# TM4C129ENCPDT register map
File version: 1.0
CPU: CORTEX_M4 1.0, other endian, MPU, FPU, 3 interrupt priority bits
Registers are 32-bit, read-write, reset 0x0 unless marked. A register's access mark holds for its fields unless they carry their own. Offsets are from the block's base; [hi:lo] are bit positions; {n}, {i} and the like mark numbered series.

## SYSCTL — System Control register addresses
Base 0x400FE000
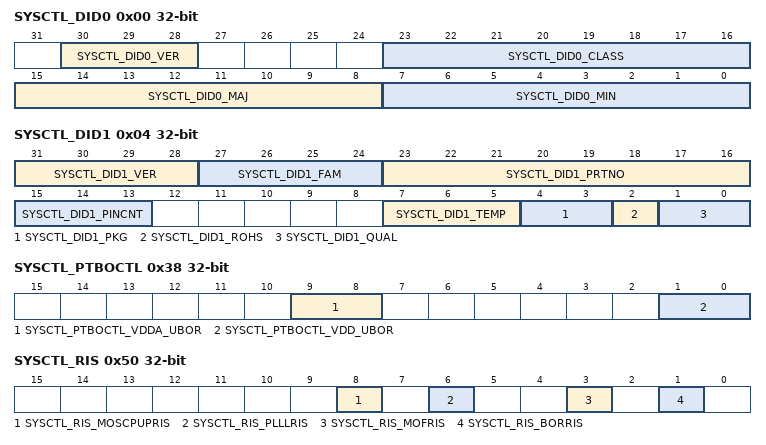
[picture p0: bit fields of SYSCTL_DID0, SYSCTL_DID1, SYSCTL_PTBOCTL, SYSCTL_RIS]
0x00 SYSCTL_DID0 — Device Identification 0
  [30:28] SYSCTL_DID0_VER — [30:28] DID0 Version
    0x10000000=Second version of the DID0 register format
  [23:16] SYSCTL_DID0_CLASS — [23:16] Device Class
    0xA0000=SYSCTL_DID0_CLASS_TM4C129 (Tiva(TM) TM4C129-class microcontrollers)
  [15:8] SYSCTL_DID0_MAJ — [15:8] Major Revision
    0=SYSCTL_DID0_MAJ_REVA (Revision A (initial device)); 0x100=SYSCTL_DID0_MAJ_REVB (Revision B (first base layer revision)); 0x200=SYSCTL_DID0_MAJ_REVC (Revision C (second base layer revision))
  [7:0] SYSCTL_DID0_MIN — [7:0] Minor Revision
    0=Initial device, or a major revision update; 1=First metal layer change; 2=Second metal layer change
0x04 SYSCTL_DID1 — Device Identification 1
  [31:28] SYSCTL_DID1_VER — [31:28] DID1 Version
  [27:24] SYSCTL_DID1_FAM — [27:24] Family
  [23:16] SYSCTL_DID1_PRTNO — [23:16] Part Number
  [15:13] SYSCTL_DID1_PINCNT — [15:13] Package Pin Count
    0x4000=100-pin LQFP package; 0x6000=64-pin LQFP package; 0x8000=144-pin LQFP package; 0xA000=157-pin BGA package; 0xC000=128-pin TQFP package
  [7:5] SYSCTL_DID1_TEMP — [7:5] Temperature Range
    0=SYSCTL_DID1_TEMP_C (Commercial temperature range); 32=SYSCTL_DID1_TEMP_I (Industrial temperature range); 64=SYSCTL_DID1_TEMP_E (Extended temperature range)
  [4:3] SYSCTL_DID1_PKG — [4:3] Package Type
    8=SYSCTL_DID1_PKG_QFP (QFP package); 16=SYSCTL_DID1_PKG_BGA (BGA package)
  [2] SYSCTL_DID1_ROHS — [2:2] RoHS-Compliance
  [1:0] SYSCTL_DID1_QUAL — [1:0] Qualification Status
    0=SYSCTL_DID1_QUAL_ES (Engineering Sample (unqualified)); 1=SYSCTL_DID1_QUAL_PP (Pilot Production (unqualified)); 2=SYSCTL_DID1_QUAL_FQ (Fully Qualified)
0x38 SYSCTL_PTBOCTL — Power-Temp Brown Out Control
  [9:8] SYSCTL_PTBOCTL_VDDA_UBOR — [9:8] VDDA under BOR Event Action
    0=SYSCTL_PTBOCTL_VDDA_UBOR_NONE (No Action); 0x100=SYSCTL_PTBOCTL_VDDA_UBOR_SYSINT (System control interrupt); 0x200=SYSCTL_PTBOCTL_VDDA_UBOR_NMI (NMI); 0x300=SYSCTL_PTBOCTL_VDDA_UBOR_RST (Reset)
  [1:0] SYSCTL_PTBOCTL_VDD_UBOR — [1:0] VDD (VDDS) under BOR Event Action
    0=SYSCTL_PTBOCTL_VDD_UBOR_NONE (No Action); 1=SYSCTL_PTBOCTL_VDD_UBOR_SYSINT (System control interrupt); 2=SYSCTL_PTBOCTL_VDD_UBOR_NMI (NMI); 3=SYSCTL_PTBOCTL_VDD_UBOR_RST (Reset)
0x50 SYSCTL_RIS — Raw Interrupt Status
  [8] SYSCTL_RIS_MOSCPUPRIS — [8:8] MOSC Power Up Raw Interrupt Status
  [6] SYSCTL_RIS_PLLLRIS — [6:6] PLL Lock Raw Interrupt Status
  [3] SYSCTL_RIS_MOFRIS — [3:3] Main Oscillator Failure Raw Interrupt Status
  [1] SYSCTL_RIS_BORRIS — [1:1] Brown-Out Reset Raw Interrupt Status
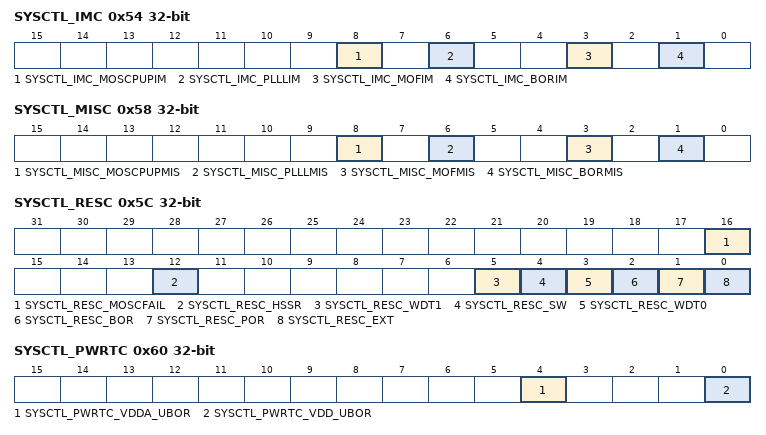
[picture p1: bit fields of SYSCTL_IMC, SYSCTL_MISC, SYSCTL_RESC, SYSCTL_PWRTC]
0x54 SYSCTL_IMC — Interrupt Mask Control
  [8] SYSCTL_IMC_MOSCPUPIM — [8:8] MOSC Power Up Interrupt Mask
  [6] SYSCTL_IMC_PLLLIM — [6:6] PLL Lock Interrupt Mask
  [3] SYSCTL_IMC_MOFIM — [3:3] Main Oscillator Failure Interrupt Mask
  [1] SYSCTL_IMC_BORIM — [1:1] Brown-Out Reset Interrupt Mask
0x58 SYSCTL_MISC — Masked Interrupt Status and Clear
  [8] SYSCTL_MISC_MOSCPUPMIS — [8:8] MOSC Power Up Masked Interrupt Status
  [6] SYSCTL_MISC_PLLLMIS — [6:6] PLL Lock Masked Interrupt Status
  [3] SYSCTL_MISC_MOFMIS — [3:3] Main Oscillator Failure Masked Interrupt Status
  [1] SYSCTL_MISC_BORMIS — [1:1] BOR Masked Interrupt Status
0x5C SYSCTL_RESC — Reset Cause
  [16] SYSCTL_RESC_MOSCFAIL — [16:16] MOSC Failure Reset
  [12] SYSCTL_RESC_HSSR — [12:12] HSSR Reset
  [5] SYSCTL_RESC_WDT1 — [5:5] Watchdog Timer 1 Reset
  [4] SYSCTL_RESC_SW — [4:4] Software Reset
  [3] SYSCTL_RESC_WDT0 — [3:3] Watchdog Timer 0 Reset
  [2] SYSCTL_RESC_BOR — [2:2] Brown-Out Reset
  [1] SYSCTL_RESC_POR — [1:1] Power-On Reset
  [0] SYSCTL_RESC_EXT — [0:0] External Reset
0x60 SYSCTL_PWRTC — Power-Temperature Cause
  [4] SYSCTL_PWRTC_VDDA_UBOR — [4:4] VDDA Under BOR Status
  [0] SYSCTL_PWRTC_VDD_UBOR — [0:0] VDD Under BOR Status
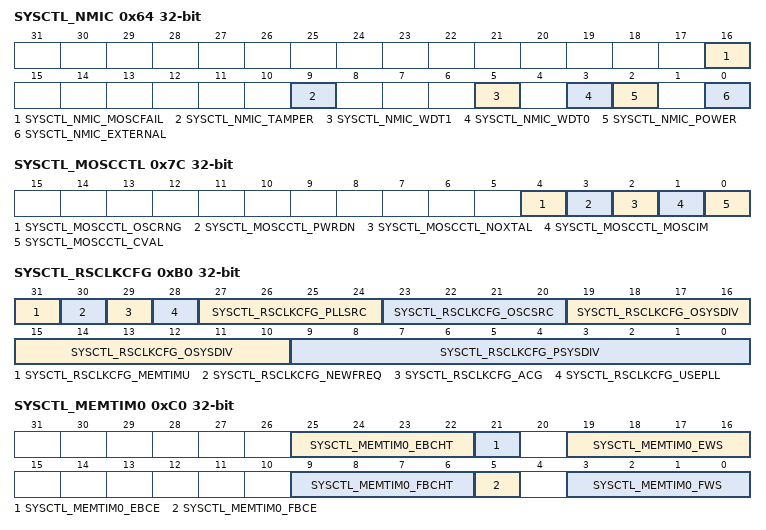
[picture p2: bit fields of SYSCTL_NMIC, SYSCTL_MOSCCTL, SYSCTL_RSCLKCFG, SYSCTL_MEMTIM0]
0x64 SYSCTL_NMIC — NMI Cause Register
  [16] SYSCTL_NMIC_MOSCFAIL — [16:16] MOSC Failure NMI
  [9] SYSCTL_NMIC_TAMPER — [9:9] Tamper Event NMI
  [5] SYSCTL_NMIC_WDT1 — [5:5] Watch Dog Timer (WDT) 1 NMI
  [3] SYSCTL_NMIC_WDT0 — [3:3] Watch Dog Timer (WDT) 0 NMI
  [2] SYSCTL_NMIC_POWER — [2:2] Power/Brown Out Event NMI
  [0] SYSCTL_NMIC_EXTERNAL — [0:0] External Pin NMI
0x7C SYSCTL_MOSCCTL — Main Oscillator Control
  [4] SYSCTL_MOSCCTL_OSCRNG — [4:4] Oscillator Range
  [3] SYSCTL_MOSCCTL_PWRDN — [3:3] Power Down
  [2] SYSCTL_MOSCCTL_NOXTAL — [2:2] No Crystal Connected
  [1] SYSCTL_MOSCCTL_MOSCIM — [1:1] MOSC Failure Action
  [0] SYSCTL_MOSCCTL_CVAL — [0:0] Clock Validation for MOSC
0xB0 SYSCTL_RSCLKCFG — Run and Sleep Mode Configuration Register
  [31] SYSCTL_RSCLKCFG_MEMTIMU — [31:31] Memory Timing Register Update
  [30] SYSCTL_RSCLKCFG_NEWFREQ — [30:30] New PLLFREQ Accept
  [29] SYSCTL_RSCLKCFG_ACG — [29:29] Auto Clock Gating
  [28] SYSCTL_RSCLKCFG_USEPLL — [28:28] Use PLL
  [27:24] SYSCTL_RSCLKCFG_PLLSRC — [27:24] PLL Source
    0=SYSCTL_RSCLKCFG_PLLSRC_PIOSC (PIOSC is PLL input clock source); 0x3000000=SYSCTL_RSCLKCFG_PLLSRC_MOSC (MOSC is the PLL input clock source)
  [23:20] SYSCTL_RSCLKCFG_OSCSRC — [23:20] Oscillator Source
    0=SYSCTL_RSCLKCFG_OSCSRC_PIOSC (PIOSC is oscillator source); 0x200000=SYSCTL_RSCLKCFG_OSCSRC_LFIOSC (LFIOSC is oscillator source); 0x300000=SYSCTL_RSCLKCFG_OSCSRC_MOSC (MOSC is oscillator source); 0x400000=SYSCTL_RSCLKCFG_OSCSRC_RTC (Hibernation Module RTC Oscillator (RTCOSC))
  [19:10] SYSCTL_RSCLKCFG_OSYSDIV — [19:10] Oscillator System Clock Divisor
  [9:0] SYSCTL_RSCLKCFG_PSYSDIV — [9:0] PLL System Clock Divisor
0xC0 SYSCTL_MEMTIM0 — Memory Timing Parameter Register 0 for Main Flash and EEPROM
  [25:22] SYSCTL_MEMTIM0_EBCHT — [25:22] EEPROM Clock High Time
    0=SYSCTL_MEMTIM0_EBCHT_0_5 (1/2 system clock period); 0x400000=1 system clock period; 0x800000=SYSCTL_MEMTIM0_EBCHT_1_5 (1.5 system clock periods); 0xC00000=2 system clock periods; 0x1000000=SYSCTL_MEMTIM0_EBCHT_2_5 (2.5 system clock periods); 0x1400000=3 system clock periods; 0x1800000=SYSCTL_MEMTIM0_EBCHT_3_5 (3.5 system clock periods); 0x1C00000=4 system clock periods; 0x2000000=SYSCTL_MEMTIM0_EBCHT_4_5 (4.5 system clock periods)
  [21] SYSCTL_MEMTIM0_EBCE — [21:21] EEPROM Bank Clock Edge
  [19:16] SYSCTL_MEMTIM0_EWS — [19:16] EEPROM Wait States
  [9:6] SYSCTL_MEMTIM0_FBCHT — [9:6] Flash Bank Clock High Time
    0=SYSCTL_MEMTIM0_FBCHT_0_5 (1/2 system clock period); 64=1 system clock period; 128=SYSCTL_MEMTIM0_FBCHT_1_5 (1.5 system clock periods); 192=2 system clock periods; 0x100=SYSCTL_MEMTIM0_FBCHT_2_5 (2.5 system clock periods); 0x140=3 system clock periods; 0x180=SYSCTL_MEMTIM0_FBCHT_3_5 (3.5 system clock periods); 0x1C0=4 system clock periods; 0x200=SYSCTL_MEMTIM0_FBCHT_4_5 (4.5 system clock periods)
  [5] SYSCTL_MEMTIM0_FBCE — [5:5] Flash Bank Clock Edge
  [3:0] SYSCTL_MEMTIM0_FWS — [3:0] Flash Wait State
0x138 SYSCTL_ALTCLKCFG — Alternate Clock Configuration
  [3:0] SYSCTL_ALTCLKCFG_ALTCLK — [3:0] Alternate Clock Source
    0=SYSCTL_ALTCLKCFG_ALTCLK_PIOSC (PIOSC); 3=SYSCTL_ALTCLKCFG_ALTCLK_RTCOSC (Hibernation Module Real-time clock output (RTCOSC)); 4=SYSCTL_ALTCLKCFG_ALTCLK_LFIOSC (Low-frequency internal oscillator (LFIOSC))
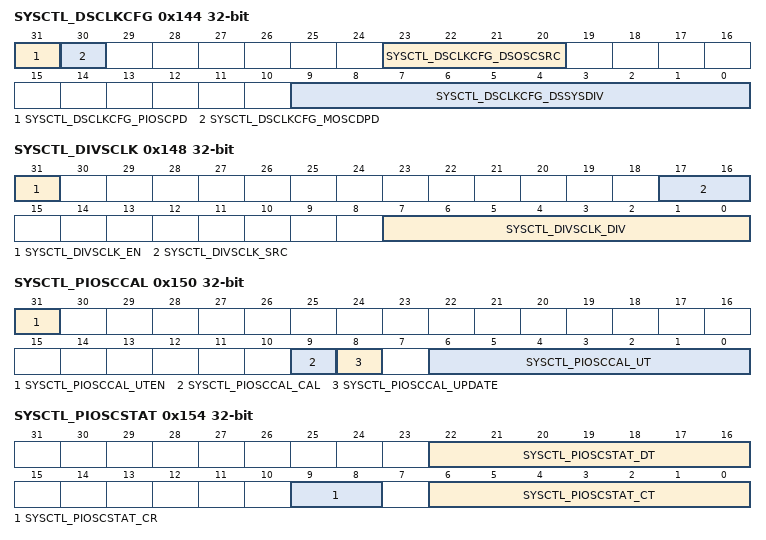
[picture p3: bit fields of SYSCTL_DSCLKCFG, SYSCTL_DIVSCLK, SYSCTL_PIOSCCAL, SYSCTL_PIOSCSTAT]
0x144 SYSCTL_DSCLKCFG — Deep Sleep Clock Configuration Register
  [31] SYSCTL_DSCLKCFG_PIOSCPD — [31:31] PIOSC Power Down
  [30] SYSCTL_DSCLKCFG_MOSCDPD — [30:30] MOSC Disable Power Down
  [23:20] SYSCTL_DSCLKCFG_DSOSCSRC — [23:20] Deep Sleep Oscillator Source
    0=SYSCTL_DSCLKCFG_DSOSCSRC_PIOSC (PIOSC); 0x200000=SYSCTL_DSCLKCFG_DSOSCSRC_LFIOSC (LFIOSC); 0x300000=SYSCTL_DSCLKCFG_DSOSCSRC_MOSC (MOSC); 0x400000=SYSCTL_DSCLKCFG_DSOSCSRC_RTC (Hibernation Module RTCOSC)
  [9:0] SYSCTL_DSCLKCFG_DSSYSDIV — [9:0] Deep Sleep Clock Divisor
0x148 SYSCTL_DIVSCLK — Divisor and Source Clock Configuration
  [31] SYSCTL_DIVSCLK_EN — [31:31] DIVSCLK Enable
  [17:16] SYSCTL_DIVSCLK_SRC — [17:16] Clock Source
    0=SYSCTL_DIVSCLK_SRC_SYSCLK (System Clock); 0x10000=SYSCTL_DIVSCLK_SRC_PIOSC (PIOSC); 0x20000=SYSCTL_DIVSCLK_SRC_MOSC (MOSC)
  [7:0] SYSCTL_DIVSCLK_DIV — [7:0] Divisor Value
0x14C SYSCTL_SYSPROP — System Properties
  [0] SYSCTL_SYSPROP_FPU — [0:0] FPU Present
0x150 SYSCTL_PIOSCCAL — Precision Internal Oscillator Calibration
  [31] SYSCTL_PIOSCCAL_UTEN — [31:31] Use User Trim Value
  [9] SYSCTL_PIOSCCAL_CAL — [9:9] Start Calibration
  [8] SYSCTL_PIOSCCAL_UPDATE — [8:8] Update Trim
  [6:0] SYSCTL_PIOSCCAL_UT — [6:0] User Trim Value
0x154 SYSCTL_PIOSCSTAT — Precision Internal Oscillator Statistics
  [22:16] SYSCTL_PIOSCSTAT_DT — [22:16] Default Trim Value
  [9:8] SYSCTL_PIOSCSTAT_CR — [9:8] Calibration Result
    0=SYSCTL_PIOSCSTAT_CRNONE (Calibration has not been attempted); 0x100=SYSCTL_PIOSCSTAT_CRPASS (The last calibration operation completed to meet 1% accuracy); 0x200=SYSCTL_PIOSCSTAT_CRFAIL (The last calibration operation failed to meet 1% accuracy)
  [6:0] SYSCTL_PIOSCSTAT_CT — [6:0] Calibration Trim Value
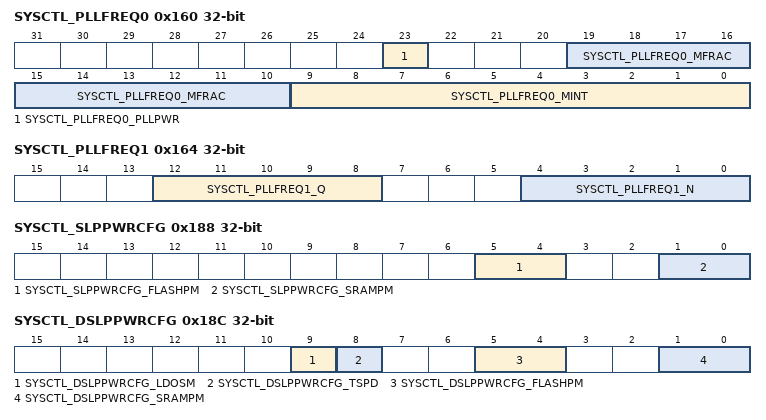
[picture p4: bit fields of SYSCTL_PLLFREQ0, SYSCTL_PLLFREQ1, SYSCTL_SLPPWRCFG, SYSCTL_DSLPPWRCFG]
0x160 SYSCTL_PLLFREQ0 — PLL Frequency 0
  [23] SYSCTL_PLLFREQ0_PLLPWR — [23:23] PLL Power
  [19:10] SYSCTL_PLLFREQ0_MFRAC — [19:10] PLL M Fractional Value
  [9:0] SYSCTL_PLLFREQ0_MINT — [9:0] PLL M Integer Value
0x164 SYSCTL_PLLFREQ1 — PLL Frequency 1
  [12:8] SYSCTL_PLLFREQ1_Q — [12:8] PLL Q Value
  [4:0] SYSCTL_PLLFREQ1_N — [4:0] PLL N Value
0x168 SYSCTL_PLLSTAT — PLL Status
  [0] SYSCTL_PLLSTAT_LOCK — [0:0] PLL Lock
0x188 SYSCTL_SLPPWRCFG — Sleep Power Configuration
  [5:4] SYSCTL_SLPPWRCFG_FLASHPM — [5:4] Flash Power Modes
    0=SYSCTL_SLPPWRCFG_FLASHPM_NRM (Active Mode); 32=SYSCTL_SLPPWRCFG_FLASHPM_SLP (Low Power Mode)
  [1:0] SYSCTL_SLPPWRCFG_SRAMPM — [1:0] SRAM Power Modes
    0=SYSCTL_SLPPWRCFG_SRAMPM_NRM (Active Mode); 1=SYSCTL_SLPPWRCFG_SRAMPM_SBY (Standby Mode); 3=SYSCTL_SLPPWRCFG_SRAMPM_LP (Low Power Mode)
0x18C SYSCTL_DSLPPWRCFG — Deep-Sleep Power Configuration
  [9] SYSCTL_DSLPPWRCFG_LDOSM — [9:9] LDO Sleep Mode
  [8] SYSCTL_DSLPPWRCFG_TSPD — [8:8] Temperature Sense Power Down
  [5:4] SYSCTL_DSLPPWRCFG_FLASHPM — [5:4] Flash Power Modes
    0=SYSCTL_DSLPPWRCFG_FLASHPM_NRM (Active Mode); 32=SYSCTL_DSLPPWRCFG_FLASHPM_SLP (Low Power Mode)
  [1:0] SYSCTL_DSLPPWRCFG_SRAMPM — [1:0] SRAM Power Modes
    0=SYSCTL_DSLPPWRCFG_SRAMPM_NRM (Active Mode); 1=SYSCTL_DSLPPWRCFG_SRAMPM_SBY (Standby Mode); 3=SYSCTL_DSLPPWRCFG_SRAMPM_LP (Low Power Mode)
0x1A0 SYSCTL_NVMSTAT — Non-Volatile Memory Information
  [0] SYSCTL_NVMSTAT_FWB — [0:0] 32 Word Flash Write Buffer Available
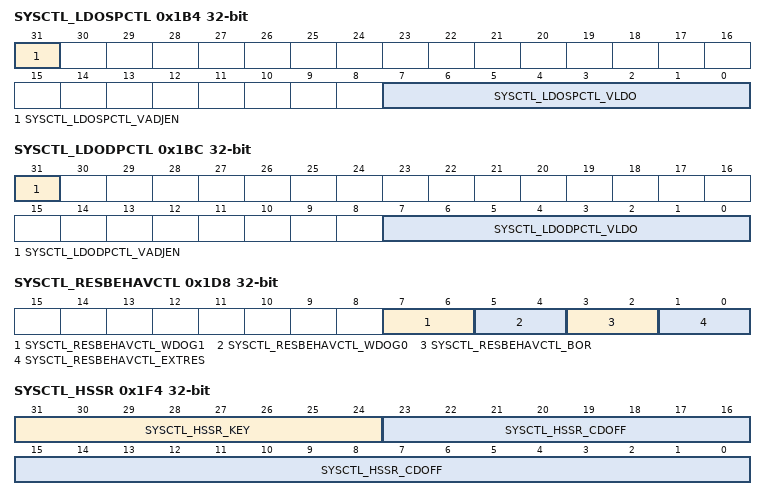
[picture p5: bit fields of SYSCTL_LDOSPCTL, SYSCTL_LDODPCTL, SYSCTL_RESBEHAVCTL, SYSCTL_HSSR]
0x1B4 SYSCTL_LDOSPCTL — LDO Sleep Power Control
  [31] SYSCTL_LDOSPCTL_VADJEN — [31:31] Voltage Adjust Enable
  [7:0] SYSCTL_LDOSPCTL_VLDO — [7:0] LDO Output Voltage
    18=SYSCTL_LDOSPCTL_VLDO_0_90V (0.90 V); 19=SYSCTL_LDOSPCTL_VLDO_0_95V (0.95 V); 20=SYSCTL_LDOSPCTL_VLDO_1_00V (1.00 V); 21=SYSCTL_LDOSPCTL_VLDO_1_05V (1.05 V); 22=SYSCTL_LDOSPCTL_VLDO_1_10V (1.10 V); 23=SYSCTL_LDOSPCTL_VLDO_1_15V (1.15 V); 24=SYSCTL_LDOSPCTL_VLDO_1_20V (1.20 V)
0x1BC SYSCTL_LDODPCTL — LDO Deep-Sleep Power Control
  [31] SYSCTL_LDODPCTL_VADJEN — [31:31] Voltage Adjust Enable
  [7:0] SYSCTL_LDODPCTL_VLDO — [7:0] LDO Output Voltage
    18=SYSCTL_LDODPCTL_VLDO_0_90V (0.90 V); 19=SYSCTL_LDODPCTL_VLDO_0_95V (0.95 V); 20=SYSCTL_LDODPCTL_VLDO_1_00V (1.00 V); 21=SYSCTL_LDODPCTL_VLDO_1_05V (1.05 V); 22=SYSCTL_LDODPCTL_VLDO_1_10V (1.10 V); 23=SYSCTL_LDODPCTL_VLDO_1_15V (1.15 V); 24=SYSCTL_LDODPCTL_VLDO_1_20V (1.20 V); 25=SYSCTL_LDODPCTL_VLDO_1_25V (1.25 V); 26=SYSCTL_LDODPCTL_VLDO_1_30V (1.30 V); 27=SYSCTL_LDODPCTL_VLDO_1_35V (1.35 V)
0x1D8 SYSCTL_RESBEHAVCTL — Reset Behavior Control Register
  [7:6] SYSCTL_RESBEHAVCTL_WDOG1 — [7:6] Watchdog 1 Reset Operation
    128=SYSCTL_RESBEHAVCTL_WDOG1_SYSRST (Watchdog 1 issues a system reset. The application starts within 10 us); 192=SYSCTL_RESBEHAVCTL_WDOG1_POR (Watchdog 1 issues a simulated POR sequence. Application starts less than 500 us after deassertion (Default))
  [5:4] SYSCTL_RESBEHAVCTL_WDOG0 — [5:4] Watchdog 0 Reset Operation
    32=SYSCTL_RESBEHAVCTL_WDOG0_SYSRST (Watchdog 0 issues a system reset. The application starts within 10 us); 48=SYSCTL_RESBEHAVCTL_WDOG0_POR (Watchdog 0 issues a simulated POR sequence. Application starts less than 500 us after deassertion (Default))
  [3:2] SYSCTL_RESBEHAVCTL_BOR — [3:2] BOR Reset operation
    8=SYSCTL_RESBEHAVCTL_BOR_SYSRST (Brown Out Reset issues system reset. The application starts within 10 us); 12=SYSCTL_RESBEHAVCTL_BOR_POR (Brown Out Reset issues a simulated POR sequence. The application starts less than 500 us after deassertion (Default))
  [1:0] SYSCTL_RESBEHAVCTL_EXTRES — [1:0] External RST Pin Operation
    2=SYSCTL_RESBEHAVCTL_EXTRES_SYSRST (External RST assertion issues a system reset. The application starts within 10 us); 3=SYSCTL_RESBEHAVCTL_EXTRES_POR (External RST assertion issues a simulated POR sequence. Application starts less than 500 us after deassertion (Default))
0x1F4 SYSCTL_HSSR — Hardware System Service Request
  [31:24] SYSCTL_HSSR_KEY — [31:24] Write Key
  [23:0] SYSCTL_HSSR_CDOFF — [23:0] Command Descriptor Pointer
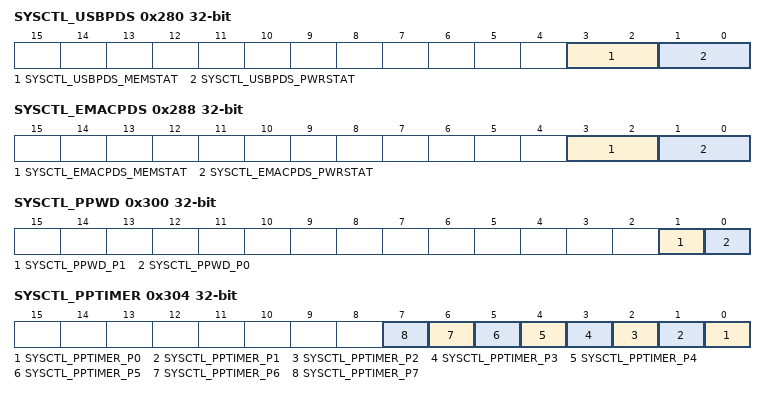
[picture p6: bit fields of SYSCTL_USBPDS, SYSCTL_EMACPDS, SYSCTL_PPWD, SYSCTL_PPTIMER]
0x280 SYSCTL_USBPDS — USB Power Domain Status
  [3:2] SYSCTL_USBPDS_MEMSTAT — [3:2] Memory Array Power Status
    0=SYSCTL_USBPDS_MEMSTAT_OFF (Array OFF); 4=SYSCTL_USBPDS_MEMSTAT_RETAIN (SRAM Retention); 12=SYSCTL_USBPDS_MEMSTAT_ON (Array On)
  [1:0] SYSCTL_USBPDS_PWRSTAT — [1:0] Power Domain Status
    0=SYSCTL_USBPDS_PWRSTAT_OFF (OFF); 3=SYSCTL_USBPDS_PWRSTAT_ON (ON)
0x284 SYSCTL_USBMPC — USB Memory Power Control
  [1:0] SYSCTL_USBMPC_PWRCTL — [1:0] Memory Array Power Control
    0=SYSCTL_USBMPC_PWRCTL_OFF (Array OFF); 1=SYSCTL_USBMPC_PWRCTL_RETAIN (SRAM Retention); 3=SYSCTL_USBMPC_PWRCTL_ON (Array On)
0x288 SYSCTL_EMACPDS — Ethernet MAC Power Domain Status
  [3:2] SYSCTL_EMACPDS_MEMSTAT — [3:2] Memory Array Power Status
    0=SYSCTL_EMACPDS_MEMSTAT_OFF (Array OFF); 12=SYSCTL_EMACPDS_MEMSTAT_ON (Array On)
  [1:0] SYSCTL_EMACPDS_PWRSTAT — [1:0] Power Domain Status
    0=SYSCTL_EMACPDS_PWRSTAT_OFF (OFF); 3=SYSCTL_EMACPDS_PWRSTAT_ON (ON)
0x28C SYSCTL_EMACMPC — Ethernet MAC Memory Power Control
  [1:0] SYSCTL_EMACMPC_PWRCTL — [1:0] Memory Array Power Control
    0=SYSCTL_EMACMPC_PWRCTL_OFF (Array OFF); 3=SYSCTL_EMACMPC_PWRCTL_ON (Array On)
0x300 SYSCTL_PPWD — Watchdog Timer Peripheral Present
  [1] SYSCTL_PPWD_P1 — [1:1] Watchdog Timer 1 Present
  [0] SYSCTL_PPWD_P0 — [0:0] Watchdog Timer 0 Present
0x304 SYSCTL_PPTIMER — 16/32-Bit General-Purpose Timer Peripheral Present
  [n] SYSCTL_PPTIMER_P{n} (n=0..7) — [{n}:{n}] 16/32-Bit General-Purpose Timer {n} Present
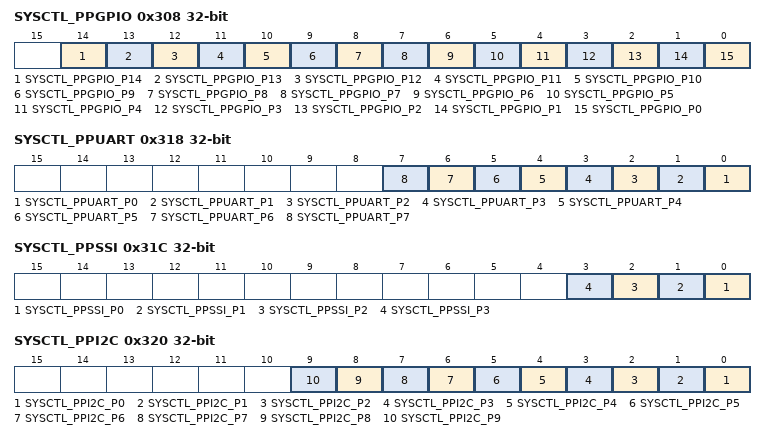
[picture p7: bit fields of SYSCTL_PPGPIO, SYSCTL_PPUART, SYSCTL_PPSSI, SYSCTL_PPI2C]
0x308 SYSCTL_PPGPIO — General-Purpose Input/Output Peripheral Present
  [14] SYSCTL_PPGPIO_P14 — [14:14] GPIO Port Q Present
  [13] SYSCTL_PPGPIO_P13 — [13:13] GPIO Port P Present
  [12] SYSCTL_PPGPIO_P12 — [12:12] GPIO Port N Present
  [11] SYSCTL_PPGPIO_P11 — [11:11] GPIO Port M Present
  [10] SYSCTL_PPGPIO_P10 — [10:10] GPIO Port L Present
  [9] SYSCTL_PPGPIO_P9 — [9:9] GPIO Port K Present
  [8] SYSCTL_PPGPIO_P8 — [8:8] GPIO Port J Present
  [7] SYSCTL_PPGPIO_P7 — [7:7] GPIO Port H Present
  [6] SYSCTL_PPGPIO_P6 — [6:6] GPIO Port G Present
  [5] SYSCTL_PPGPIO_P5 — [5:5] GPIO Port F Present
  [4] SYSCTL_PPGPIO_P4 — [4:4] GPIO Port E Present
  [3] SYSCTL_PPGPIO_P3 — [3:3] GPIO Port D Present
  [2] SYSCTL_PPGPIO_P2 — [2:2] GPIO Port C Present
  [1] SYSCTL_PPGPIO_P1 — [1:1] GPIO Port B Present
  [0] SYSCTL_PPGPIO_P0 — [0:0] GPIO Port A Present
0x30C SYSCTL_PPDMA — Micro Direct Memory Access Peripheral Present
  [0] SYSCTL_PPDMA_P0 — [0:0] uDMA Module Present
0x310 SYSCTL_PPEPI — EPI Peripheral Present
  [0] SYSCTL_PPEPI_P0 — [0:0] EPI Module Present
0x314 SYSCTL_PPHIB — Hibernation Peripheral Present
  [0] SYSCTL_PPHIB_P0 — [0:0] Hibernation Module Present
0x318 SYSCTL_PPUART — Universal Asynchronous Receiver/Transmitter Peripheral Present
  [n] SYSCTL_PPUART_P{n} (n=0..7) — [{n}:{n}] UART Module {n} Present
0x31C SYSCTL_PPSSI — Synchronous Serial Interface Peripheral Present
  [n] SYSCTL_PPSSI_P{n} (n=0..3) — [{n}:{n}] SSI Module {n} Present
0x320 SYSCTL_PPI2C — Inter-Integrated Circuit Peripheral Present
  [n] SYSCTL_PPI2C_P{n} (n=0..9) — [{n}:{n}] I2C Module {n} Present
0x328 SYSCTL_PPUSB — Universal Serial Bus Peripheral Present
  [0] SYSCTL_PPUSB_P0 — [0:0] USB Module Present
0x330 SYSCTL_PPEPHY — Ethernet PHY Peripheral Present
  [0] SYSCTL_PPEPHY_P0 — [0:0] Ethernet PHY Module Present
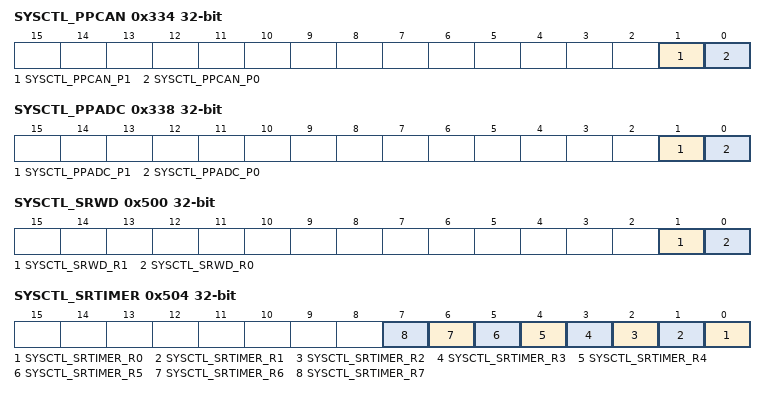
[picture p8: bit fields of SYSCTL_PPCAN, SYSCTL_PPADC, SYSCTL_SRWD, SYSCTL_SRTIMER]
0x334 SYSCTL_PPCAN — Controller Area Network Peripheral Present
  [1] SYSCTL_PPCAN_P1 — [1:1] CAN Module 1 Present
  [0] SYSCTL_PPCAN_P0 — [0:0] CAN Module 0 Present
0x338 SYSCTL_PPADC — Analog-to-Digital Converter Peripheral Present
  [1] SYSCTL_PPADC_P1 — [1:1] ADC Module 1 Present
  [0] SYSCTL_PPADC_P0 — [0:0] ADC Module 0 Present
0x33C SYSCTL_PPACMP — Analog Comparator Peripheral Present
  [0] SYSCTL_PPACMP_P0 — [0:0] Analog Comparator Module Present
0x340 SYSCTL_PPPWM — Pulse Width Modulator Peripheral Present
  [0] SYSCTL_PPPWM_P0 — [0:0] PWM Module 0 Present
0x344 SYSCTL_PPQEI — Quadrature Encoder Interface Peripheral Present
  [0] SYSCTL_PPQEI_P0 — [0:0] QEI Module 0 Present
0x348 SYSCTL_PPLPC — Low Pin Count Interface Peripheral Present
  [0] SYSCTL_PPLPC_P0 — [0:0] LPC Module Present
0x350 SYSCTL_PPPECI — Platform Environment Control Interface Peripheral Present
  [0] SYSCTL_PPPECI_P0 — [0:0] PECI Module Present
0x354 SYSCTL_PPFAN — Fan Control Peripheral Present
  [0] SYSCTL_PPFAN_P0 — [0:0] FAN Module 0 Present
0x358 SYSCTL_PPEEPROM — EEPROM Peripheral Present
  [0] SYSCTL_PPEEPROM_P0 — [0:0] EEPROM Module Present
0x35C SYSCTL_PPWTIMER — 32/64-Bit Wide General-Purpose Timer Peripheral Present
  [0] SYSCTL_PPWTIMER_P0 — [0:0] 32/64-Bit Wide General-Purpose Timer 0 Present
0x370 SYSCTL_PPRTS — Remote Temperature Sensor Peripheral Present
  [0] SYSCTL_PPRTS_P0 — [0:0] RTS Module Present
0x374 SYSCTL_PPCCM — CRC and Cryptographic Modules Peripheral Present
  [0] SYSCTL_PPCCM_P0 — [0:0] CRC and Cryptographic Modules Present
0x390 SYSCTL_PPLCD — LCD Peripheral Present
  [0] SYSCTL_PPLCD_P0 — [0:0] LCD Module Present
0x398 SYSCTL_PPOWIRE — 1-Wire Peripheral Present
  [0] SYSCTL_PPOWIRE_P0 — [0:0] 1-Wire Module Present
0x39C SYSCTL_PPEMAC — Ethernet MAC Peripheral Present
  [0] SYSCTL_PPEMAC_P0 — [0:0] Ethernet Controller Module Present
0x3A4 SYSCTL_PPHIM — Human Interface Master Peripheral Present
  [0] SYSCTL_PPHIM_P0 — [0:0] HIM Module Present
0x500 SYSCTL_SRWD — Watchdog Timer Software Reset
  [1] SYSCTL_SRWD_R1 — [1:1] Watchdog Timer 1 Software Reset
  [0] SYSCTL_SRWD_R0 — [0:0] Watchdog Timer 0 Software Reset
0x504 SYSCTL_SRTIMER — 16/32-Bit General-Purpose Timer Software Reset
  [n] SYSCTL_SRTIMER_R{n} (n=0..7) — [{n}:{n}] 16/32-Bit General-Purpose Timer {n} Software Reset
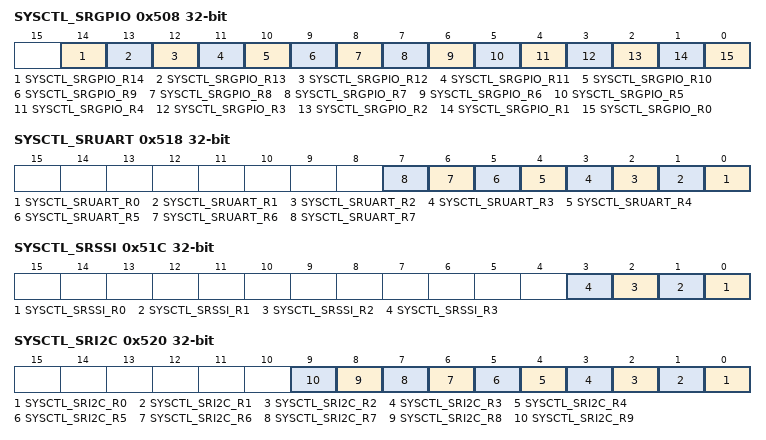
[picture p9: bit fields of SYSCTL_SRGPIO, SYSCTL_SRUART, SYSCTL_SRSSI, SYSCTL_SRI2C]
0x508 SYSCTL_SRGPIO — General-Purpose Input/Output Software Reset
  [14] SYSCTL_SRGPIO_R14 — [14:14] GPIO Port Q Software Reset
  [13] SYSCTL_SRGPIO_R13 — [13:13] GPIO Port P Software Reset
  [12] SYSCTL_SRGPIO_R12 — [12:12] GPIO Port N Software Reset
  [11] SYSCTL_SRGPIO_R11 — [11:11] GPIO Port M Software Reset
  [10] SYSCTL_SRGPIO_R10 — [10:10] GPIO Port L Software Reset
  [9] SYSCTL_SRGPIO_R9 — [9:9] GPIO Port K Software Reset
  [8] SYSCTL_SRGPIO_R8 — [8:8] GPIO Port J Software Reset
  [7] SYSCTL_SRGPIO_R7 — [7:7] GPIO Port H Software Reset
  [6] SYSCTL_SRGPIO_R6 — [6:6] GPIO Port G Software Reset
  [5] SYSCTL_SRGPIO_R5 — [5:5] GPIO Port F Software Reset
  [4] SYSCTL_SRGPIO_R4 — [4:4] GPIO Port E Software Reset
  [3] SYSCTL_SRGPIO_R3 — [3:3] GPIO Port D Software Reset
  [2] SYSCTL_SRGPIO_R2 — [2:2] GPIO Port C Software Reset
  [1] SYSCTL_SRGPIO_R1 — [1:1] GPIO Port B Software Reset
  [0] SYSCTL_SRGPIO_R0 — [0:0] GPIO Port A Software Reset
0x50C SYSCTL_SRDMA — Micro Direct Memory Access Software Reset
  [0] SYSCTL_SRDMA_R0 — [0:0] uDMA Module Software Reset
0x510 SYSCTL_SREPI — EPI Software Reset
  [0] SYSCTL_SREPI_R0 — [0:0] EPI Module Software Reset
0x514 SYSCTL_SRHIB — Hibernation Software Reset
  [0] SYSCTL_SRHIB_R0 — [0:0] Hibernation Module Software Reset
0x518 SYSCTL_SRUART — Universal Asynchronous Receiver/Transmitter Software Reset
  [n] SYSCTL_SRUART_R{n} (n=0..7) — [{n}:{n}] UART Module {n} Software Reset
0x51C SYSCTL_SRSSI — Synchronous Serial Interface Software Reset
  [n] SYSCTL_SRSSI_R{n} (n=0..3) — [{n}:{n}] SSI Module {n} Software Reset
0x520 SYSCTL_SRI2C — Inter-Integrated Circuit Software Reset
  [n] SYSCTL_SRI2C_R{n} (n=0..9) — [{n}:{n}] I2C Module {n} Software Reset
0x528 SYSCTL_SRUSB — Universal Serial Bus Software Reset
  [0] SYSCTL_SRUSB_R0 — [0:0] USB Module Software Reset
0x530 SYSCTL_SREPHY — Ethernet PHY Software Reset
  [0] SYSCTL_SREPHY_R0 — [0:0] Ethernet PHY Module Software Reset
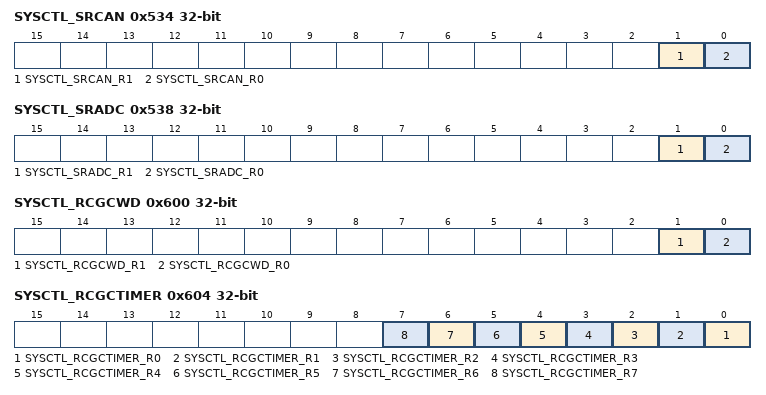
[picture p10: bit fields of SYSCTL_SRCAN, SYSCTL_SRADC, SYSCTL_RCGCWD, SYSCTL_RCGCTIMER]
0x534 SYSCTL_SRCAN — Controller Area Network Software Reset
  [1] SYSCTL_SRCAN_R1 — [1:1] CAN Module 1 Software Reset
  [0] SYSCTL_SRCAN_R0 — [0:0] CAN Module 0 Software Reset
0x538 SYSCTL_SRADC — Analog-to-Digital Converter Software Reset
  [1] SYSCTL_SRADC_R1 — [1:1] ADC Module 1 Software Reset
  [0] SYSCTL_SRADC_R0 — [0:0] ADC Module 0 Software Reset
0x53C SYSCTL_SRACMP — Analog Comparator Software Reset
  [0] SYSCTL_SRACMP_R0 — [0:0] Analog Comparator Module 0 Software Reset
0x540 SYSCTL_SRPWM — Pulse Width Modulator Software Reset
  [0] SYSCTL_SRPWM_R0 — [0:0] PWM Module 0 Software Reset
0x544 SYSCTL_SRQEI — Quadrature Encoder Interface Software Reset
  [0] SYSCTL_SRQEI_R0 — [0:0] QEI Module 0 Software Reset
0x558 SYSCTL_SREEPROM — EEPROM Software Reset
  [0] SYSCTL_SREEPROM_R0 — [0:0] EEPROM Module Software Reset
0x574 SYSCTL_SRCCM — CRC and Cryptographic Modules Software Reset
  [0] SYSCTL_SRCCM_R0 — [0:0] CRC and Cryptographic Modules Software Reset
0x59C SYSCTL_SREMAC — Ethernet MAC Software Reset
  [0] SYSCTL_SREMAC_R0 — [0:0] Ethernet Controller MAC Module 0 Software Reset
0x600 SYSCTL_RCGCWD — Watchdog Timer Run Mode Clock Gating Control
  [1] SYSCTL_RCGCWD_R1 — [1:1] Watchdog Timer 1 Run Mode Clock Gating Control
  [0] SYSCTL_RCGCWD_R0 — [0:0] Watchdog Timer 0 Run Mode Clock Gating Control
0x604 SYSCTL_RCGCTIMER — 16/32-Bit General-Purpose Timer Run Mode Clock Gating Control
  [n] SYSCTL_RCGCTIMER_R{n} (n=0..7) — [{n}:{n}] 16/32-Bit General-Purpose Timer {n} Run Mode Clock Gating Control
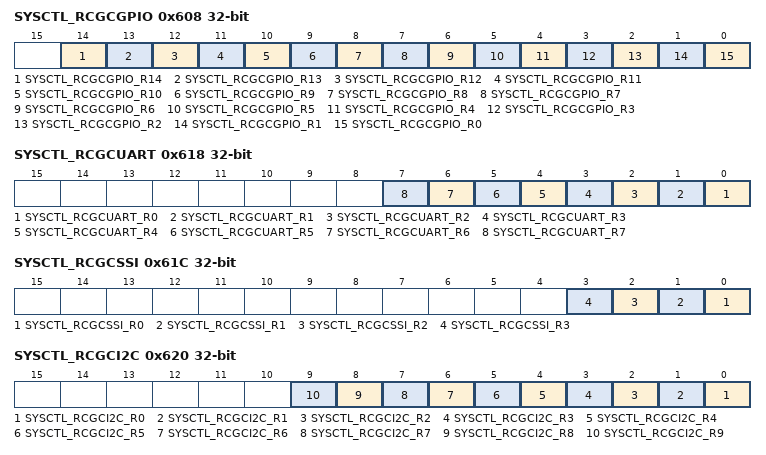
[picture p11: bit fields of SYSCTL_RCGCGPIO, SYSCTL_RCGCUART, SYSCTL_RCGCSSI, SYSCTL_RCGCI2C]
0x608 SYSCTL_RCGCGPIO — General-Purpose Input/Output Run Mode Clock Gating Control
  [14] SYSCTL_RCGCGPIO_R14 — [14:14] GPIO Port Q Run Mode Clock Gating Control
  [13] SYSCTL_RCGCGPIO_R13 — [13:13] GPIO Port P Run Mode Clock Gating Control
  [12] SYSCTL_RCGCGPIO_R12 — [12:12] GPIO Port N Run Mode Clock Gating Control
  [11] SYSCTL_RCGCGPIO_R11 — [11:11] GPIO Port M Run Mode Clock Gating Control
  [10] SYSCTL_RCGCGPIO_R10 — [10:10] GPIO Port L Run Mode Clock Gating Control
  [9] SYSCTL_RCGCGPIO_R9 — [9:9] GPIO Port K Run Mode Clock Gating Control
  [8] SYSCTL_RCGCGPIO_R8 — [8:8] GPIO Port J Run Mode Clock Gating Control
  [7] SYSCTL_RCGCGPIO_R7 — [7:7] GPIO Port H Run Mode Clock Gating Control
  [6] SYSCTL_RCGCGPIO_R6 — [6:6] GPIO Port G Run Mode Clock Gating Control
  [5] SYSCTL_RCGCGPIO_R5 — [5:5] GPIO Port F Run Mode Clock Gating Control
  [4] SYSCTL_RCGCGPIO_R4 — [4:4] GPIO Port E Run Mode Clock Gating Control
  [3] SYSCTL_RCGCGPIO_R3 — [3:3] GPIO Port D Run Mode Clock Gating Control
  [2] SYSCTL_RCGCGPIO_R2 — [2:2] GPIO Port C Run Mode Clock Gating Control
  [1] SYSCTL_RCGCGPIO_R1 — [1:1] GPIO Port B Run Mode Clock Gating Control
  [0] SYSCTL_RCGCGPIO_R0 — [0:0] GPIO Port A Run Mode Clock Gating Control
0x60C SYSCTL_RCGCDMA — Micro Direct Memory Access Run Mode Clock Gating Control
  [0] SYSCTL_RCGCDMA_R0 — [0:0] uDMA Module Run Mode Clock Gating Control
0x610 SYSCTL_RCGCEPI — EPI Run Mode Clock Gating Control
  [0] SYSCTL_RCGCEPI_R0 — [0:0] EPI Module Run Mode Clock Gating Control
0x614 SYSCTL_RCGCHIB — Hibernation Run Mode Clock Gating Control
  [0] SYSCTL_RCGCHIB_R0 — [0:0] Hibernation Module Run Mode Clock Gating Control
0x618 SYSCTL_RCGCUART — Universal Asynchronous Receiver/Transmitter Run Mode Clock Gating Control
  [n] SYSCTL_RCGCUART_R{n} (n=0..7) — [{n}:{n}] UART Module {n} Run Mode Clock Gating Control
0x61C SYSCTL_RCGCSSI — Synchronous Serial Interface Run Mode Clock Gating Control
  [n] SYSCTL_RCGCSSI_R{n} (n=0..3) — [{n}:{n}] SSI Module {n} Run Mode Clock Gating Control
0x620 SYSCTL_RCGCI2C — Inter-Integrated Circuit Run Mode Clock Gating Control
  [n] SYSCTL_RCGCI2C_R{n} (n=0..9) — [{n}:{n}] I2C Module {n} Run Mode Clock Gating Control
0x628 SYSCTL_RCGCUSB — Universal Serial Bus Run Mode Clock Gating Control
  [0] SYSCTL_RCGCUSB_R0 — [0:0] USB Module Run Mode Clock Gating Control
0x630 SYSCTL_RCGCEPHY — Ethernet PHY Run Mode Clock Gating Control
  [0] SYSCTL_RCGCEPHY_R0 — [0:0] Ethernet PHY Module Run Mode Clock Gating Control
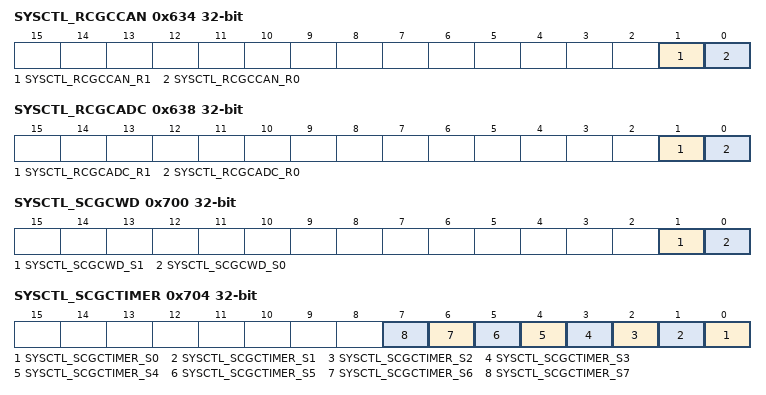
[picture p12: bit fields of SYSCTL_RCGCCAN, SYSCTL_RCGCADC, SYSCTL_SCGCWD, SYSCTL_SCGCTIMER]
0x634 SYSCTL_RCGCCAN — Controller Area Network Run Mode Clock Gating Control
  [1] SYSCTL_RCGCCAN_R1 — [1:1] CAN Module 1 Run Mode Clock Gating Control
  [0] SYSCTL_RCGCCAN_R0 — [0:0] CAN Module 0 Run Mode Clock Gating Control
0x638 SYSCTL_RCGCADC — Analog-to-Digital Converter Run Mode Clock Gating Control
  [1] SYSCTL_RCGCADC_R1 — [1:1] ADC Module 1 Run Mode Clock Gating Control
  [0] SYSCTL_RCGCADC_R0 — [0:0] ADC Module 0 Run Mode Clock Gating Control
0x63C SYSCTL_RCGCACMP — Analog Comparator Run Mode Clock Gating Control
  [0] SYSCTL_RCGCACMP_R0 — [0:0] Analog Comparator Module 0 Run Mode Clock Gating Control
0x640 SYSCTL_RCGCPWM — Pulse Width Modulator Run Mode Clock Gating Control
  [0] SYSCTL_RCGCPWM_R0 — [0:0] PWM Module 0 Run Mode Clock Gating Control
0x644 SYSCTL_RCGCQEI — Quadrature Encoder Interface Run Mode Clock Gating Control
  [0] SYSCTL_RCGCQEI_R0 — [0:0] QEI Module 0 Run Mode Clock Gating Control
0x658 SYSCTL_RCGCEEPROM — EEPROM Run Mode Clock Gating Control
  [0] SYSCTL_RCGCEEPROM_R0 — [0:0] EEPROM Module Run Mode Clock Gating Control
0x674 SYSCTL_RCGCCCM — CRC and Cryptographic Modules Run Mode Clock Gating Control
  [0] SYSCTL_RCGCCCM_R0 — [0:0] CRC and Cryptographic Modules Run Mode Clock Gating Control
0x69C SYSCTL_RCGCEMAC — Ethernet MAC Run Mode Clock Gating Control
  [0] SYSCTL_RCGCEMAC_R0 — [0:0] Ethernet MAC Module 0 Run Mode Clock Gating Control
0x700 SYSCTL_SCGCWD — Watchdog Timer Sleep Mode Clock Gating Control
  [1] SYSCTL_SCGCWD_S1 — [1:1] Watchdog Timer 1 Sleep Mode Clock Gating Control
  [0] SYSCTL_SCGCWD_S0 — [0:0] Watchdog Timer 0 Sleep Mode Clock Gating Control
0x704 SYSCTL_SCGCTIMER — 16/32-Bit General-Purpose Timer Sleep Mode Clock Gating Control
  [n] SYSCTL_SCGCTIMER_S{n} (n=0..7) — [{n}:{n}] 16/32-Bit General-Purpose Timer {n} Sleep Mode Clock Gating Control
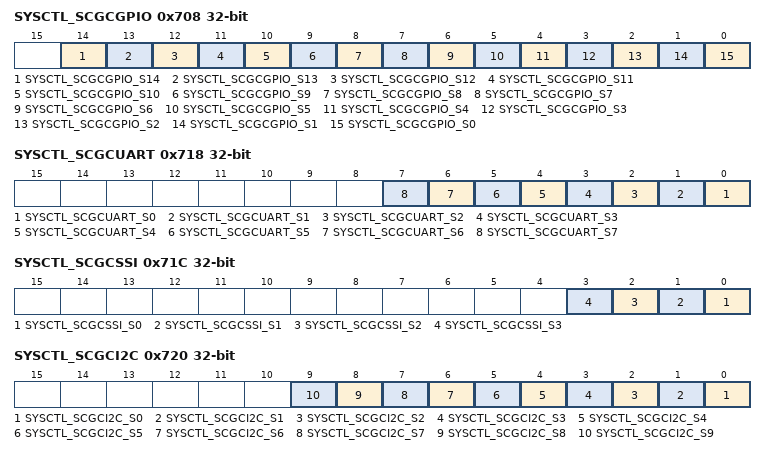
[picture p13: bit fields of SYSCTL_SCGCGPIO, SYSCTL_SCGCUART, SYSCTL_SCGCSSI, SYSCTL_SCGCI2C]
0x708 SYSCTL_SCGCGPIO — General-Purpose Input/Output Sleep Mode Clock Gating Control
  [14] SYSCTL_SCGCGPIO_S14 — [14:14] GPIO Port Q Sleep Mode Clock Gating Control
  [13] SYSCTL_SCGCGPIO_S13 — [13:13] GPIO Port P Sleep Mode Clock Gating Control
  [12] SYSCTL_SCGCGPIO_S12 — [12:12] GPIO Port N Sleep Mode Clock Gating Control
  [11] SYSCTL_SCGCGPIO_S11 — [11:11] GPIO Port M Sleep Mode Clock Gating Control
  [10] SYSCTL_SCGCGPIO_S10 — [10:10] GPIO Port L Sleep Mode Clock Gating Control
  [9] SYSCTL_SCGCGPIO_S9 — [9:9] GPIO Port K Sleep Mode Clock Gating Control
  [8] SYSCTL_SCGCGPIO_S8 — [8:8] GPIO Port J Sleep Mode Clock Gating Control
  [7] SYSCTL_SCGCGPIO_S7 — [7:7] GPIO Port H Sleep Mode Clock Gating Control
  [6] SYSCTL_SCGCGPIO_S6 — [6:6] GPIO Port G Sleep Mode Clock Gating Control
  [5] SYSCTL_SCGCGPIO_S5 — [5:5] GPIO Port F Sleep Mode Clock Gating Control
  [4] SYSCTL_SCGCGPIO_S4 — [4:4] GPIO Port E Sleep Mode Clock Gating Control
  [3] SYSCTL_SCGCGPIO_S3 — [3:3] GPIO Port D Sleep Mode Clock Gating Control
  [2] SYSCTL_SCGCGPIO_S2 — [2:2] GPIO Port C Sleep Mode Clock Gating Control
  [1] SYSCTL_SCGCGPIO_S1 — [1:1] GPIO Port B Sleep Mode Clock Gating Control
  [0] SYSCTL_SCGCGPIO_S0 — [0:0] GPIO Port A Sleep Mode Clock Gating Control
0x70C SYSCTL_SCGCDMA — Micro Direct Memory Access Sleep Mode Clock Gating Control
  [0] SYSCTL_SCGCDMA_S0 — [0:0] uDMA Module Sleep Mode Clock Gating Control
0x710 SYSCTL_SCGCEPI — EPI Sleep Mode Clock Gating Control
  [0] SYSCTL_SCGCEPI_S0 — [0:0] EPI Module Sleep Mode Clock Gating Control
0x714 SYSCTL_SCGCHIB — Hibernation Sleep Mode Clock Gating Control
  [0] SYSCTL_SCGCHIB_S0 — [0:0] Hibernation Module Sleep Mode Clock Gating Control
0x718 SYSCTL_SCGCUART — Universal Asynchronous Receiver/Transmitter Sleep Mode Clock Gating Control
  [n] SYSCTL_SCGCUART_S{n} (n=0..7) — [{n}:{n}] UART Module {n} Sleep Mode Clock Gating Control
0x71C SYSCTL_SCGCSSI — Synchronous Serial Interface Sleep Mode Clock Gating Control
  [n] SYSCTL_SCGCSSI_S{n} (n=0..3) — [{n}:{n}] SSI Module {n} Sleep Mode Clock Gating Control
0x720 SYSCTL_SCGCI2C — Inter-Integrated Circuit Sleep Mode Clock Gating Control
  [n] SYSCTL_SCGCI2C_S{n} (n=0..9) — [{n}:{n}] I2C Module {n} Sleep Mode Clock Gating Control
0x728 SYSCTL_SCGCUSB — Universal Serial Bus Sleep Mode Clock Gating Control
  [0] SYSCTL_SCGCUSB_S0 — [0:0] USB Module Sleep Mode Clock Gating Control
0x730 SYSCTL_SCGCEPHY — Ethernet PHY Sleep Mode Clock Gating Control
  [0] SYSCTL_SCGCEPHY_S0 — [0:0] PHY Module Sleep Mode Clock Gating Control
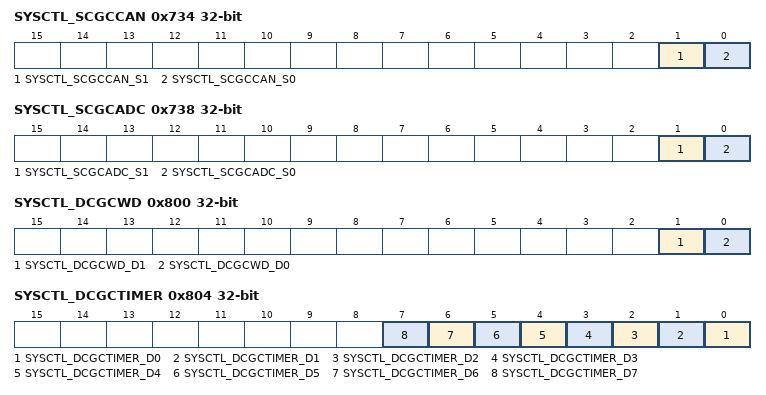
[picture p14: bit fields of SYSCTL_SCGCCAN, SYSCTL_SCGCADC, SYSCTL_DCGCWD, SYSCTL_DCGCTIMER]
0x734 SYSCTL_SCGCCAN — Controller Area Network Sleep Mode Clock Gating Control
  [1] SYSCTL_SCGCCAN_S1 — [1:1] CAN Module 1 Sleep Mode Clock Gating Control
  [0] SYSCTL_SCGCCAN_S0 — [0:0] CAN Module 0 Sleep Mode Clock Gating Control
0x738 SYSCTL_SCGCADC — Analog-to-Digital Converter Sleep Mode Clock Gating Control
  [1] SYSCTL_SCGCADC_S1 — [1:1] ADC Module 1 Sleep Mode Clock Gating Control
  [0] SYSCTL_SCGCADC_S0 — [0:0] ADC Module 0 Sleep Mode Clock Gating Control
0x73C SYSCTL_SCGCACMP — Analog Comparator Sleep Mode Clock Gating Control
  [0] SYSCTL_SCGCACMP_S0 — [0:0] Analog Comparator Module 0 Sleep Mode Clock Gating Control
0x740 SYSCTL_SCGCPWM — Pulse Width Modulator Sleep Mode Clock Gating Control
  [0] SYSCTL_SCGCPWM_S0 — [0:0] PWM Module 0 Sleep Mode Clock Gating Control
0x744 SYSCTL_SCGCQEI — Quadrature Encoder Interface Sleep Mode Clock Gating Control
  [0] SYSCTL_SCGCQEI_S0 — [0:0] QEI Module 0 Sleep Mode Clock Gating Control
0x758 SYSCTL_SCGCEEPROM — EEPROM Sleep Mode Clock Gating Control
  [0] SYSCTL_SCGCEEPROM_S0 — [0:0] EEPROM Module Sleep Mode Clock Gating Control
0x774 SYSCTL_SCGCCCM — CRC and Cryptographic Modules Sleep Mode Clock Gating Control
  [0] SYSCTL_SCGCCCM_S0 — [0:0] CRC and Cryptographic Modules Sleep Mode Clock Gating Control
0x79C SYSCTL_SCGCEMAC — Ethernet MAC Sleep Mode Clock Gating Control
  [0] SYSCTL_SCGCEMAC_S0 — [0:0] Ethernet MAC Module 0 Sleep Mode Clock Gating Control
0x800 SYSCTL_DCGCWD — Watchdog Timer Deep-Sleep Mode Clock Gating Control
  [1] SYSCTL_DCGCWD_D1 — [1:1] Watchdog Timer 1 Deep-Sleep Mode Clock Gating Control
  [0] SYSCTL_DCGCWD_D0 — [0:0] Watchdog Timer 0 Deep-Sleep Mode Clock Gating Control
0x804 SYSCTL_DCGCTIMER — 16/32-Bit General-Purpose Timer Deep-Sleep Mode Clock Gating Control
  [n] SYSCTL_DCGCTIMER_D{n} (n=0..7) — [{n}:{n}] 16/32-Bit General-Purpose Timer {n} Deep-Sleep Mode Clock Gating Control
0x808 SYSCTL_DCGCGPIO — General-Purpose Input/Output Deep-Sleep Mode Clock Gating Control
  [14] SYSCTL_DCGCGPIO_D14 — [14:14] GPIO Port Q Deep-Sleep Mode Clock Gating Control
  [13] SYSCTL_DCGCGPIO_D13 — [13:13] GPIO Port P Deep-Sleep Mode Clock Gating Control
  [12] SYSCTL_DCGCGPIO_D12 — [12:12] GPIO Port N Deep-Sleep Mode Clock Gating Control
  [11] SYSCTL_DCGCGPIO_D11 — [11:11] GPIO Port M Deep-Sleep Mode Clock Gating Control
  [10] SYSCTL_DCGCGPIO_D10 — [10:10] GPIO Port L Deep-Sleep Mode Clock Gating Control
  [9] SYSCTL_DCGCGPIO_D9 — [9:9] GPIO Port K Deep-Sleep Mode Clock Gating Control
  [8] SYSCTL_DCGCGPIO_D8 — [8:8] GPIO Port J Deep-Sleep Mode Clock Gating Control
  [7] SYSCTL_DCGCGPIO_D7 — [7:7] GPIO Port H Deep-Sleep Mode Clock Gating Control
  [6] SYSCTL_DCGCGPIO_D6 — [6:6] GPIO Port G Deep-Sleep Mode Clock Gating Control
  [5] SYSCTL_DCGCGPIO_D5 — [5:5] GPIO Port F Deep-Sleep Mode Clock Gating Control
  [4] SYSCTL_DCGCGPIO_D4 — [4:4] GPIO Port E Deep-Sleep Mode Clock Gating Control
  [3] SYSCTL_DCGCGPIO_D3 — [3:3] GPIO Port D Deep-Sleep Mode Clock Gating Control
  [2] SYSCTL_DCGCGPIO_D2 — [2:2] GPIO Port C Deep-Sleep Mode Clock Gating Control
  [1] SYSCTL_DCGCGPIO_D1 — [1:1] GPIO Port B Deep-Sleep Mode Clock Gating Control
  [0] SYSCTL_DCGCGPIO_D0 — [0:0] GPIO Port A Deep-Sleep Mode Clock Gating Control
0x80C SYSCTL_DCGCDMA — Micro Direct Memory Access Deep-Sleep Mode Clock Gating Control
  [0] SYSCTL_DCGCDMA_D0 — [0:0] uDMA Module Deep-Sleep Mode Clock Gating Control
0x810 SYSCTL_DCGCEPI — EPI Deep-Sleep Mode Clock Gating Control
  [0] SYSCTL_DCGCEPI_D0 — [0:0] EPI Module Deep-Sleep Mode Clock Gating Control
0x814 SYSCTL_DCGCHIB — Hibernation Deep-Sleep Mode Clock Gating Control
  [0] SYSCTL_DCGCHIB_D0 — [0:0] Hibernation Module Deep-Sleep Mode Clock Gating Control
0x818 SYSCTL_DCGCUART — Universal Asynchronous Receiver/Transmitter Deep-Sleep Mode Clock Gating Control
  [n] SYSCTL_DCGCUART_D{n} (n=0..7) — [{n}:{n}] UART Module {n} Deep-Sleep Mode Clock Gating Control
0x81C SYSCTL_DCGCSSI — Synchronous Serial Interface Deep-Sleep Mode Clock Gating Control
  [n] SYSCTL_DCGCSSI_D{n} (n=0..3) — [{n}:{n}] SSI Module {n} Deep-Sleep Mode Clock Gating Control
0x820 SYSCTL_DCGCI2C — Inter-Integrated Circuit Deep-Sleep Mode Clock Gating Control
  [n] SYSCTL_DCGCI2C_D{n} (n=0..9) — [{n}:{n}] I2C Module {n} Deep-Sleep Mode Clock Gating Control
0x828 SYSCTL_DCGCUSB — Universal Serial Bus Deep-Sleep Mode Clock Gating Control
  [0] SYSCTL_DCGCUSB_D0 — [0:0] USB Module Deep-Sleep Mode Clock Gating Control
0x830 SYSCTL_DCGCEPHY — Ethernet PHY Deep-Sleep Mode Clock Gating Control
  [0] SYSCTL_DCGCEPHY_D0 — [0:0] PHY Module Deep-Sleep Mode Clock Gating Control
0x834 SYSCTL_DCGCCAN — Controller Area Network Deep-Sleep Mode Clock Gating Control
  [1] SYSCTL_DCGCCAN_D1 — [1:1] CAN Module 1 Deep-Sleep Mode Clock Gating Control
  [0] SYSCTL_DCGCCAN_D0 — [0:0] CAN Module 0 Deep-Sleep Mode Clock Gating Control
0x838 SYSCTL_DCGCADC — Analog-to-Digital Converter Deep-Sleep Mode Clock Gating Control
  [1] SYSCTL_DCGCADC_D1 — [1:1] ADC Module 1 Deep-Sleep Mode Clock Gating Control
  [0] SYSCTL_DCGCADC_D0 — [0:0] ADC Module 0 Deep-Sleep Mode Clock Gating Control
0x83C SYSCTL_DCGCACMP — Analog Comparator Deep-Sleep Mode Clock Gating Control
  [0] SYSCTL_DCGCACMP_D0 — [0:0] Analog Comparator Module 0 Deep-Sleep Mode Clock Gating Control
0x840 SYSCTL_DCGCPWM — Pulse Width Modulator Deep-Sleep Mode Clock Gating Control
  [0] SYSCTL_DCGCPWM_D0 — [0:0] PWM Module 0 Deep-Sleep Mode Clock Gating Control
0x844 SYSCTL_DCGCQEI — Quadrature Encoder Interface Deep-Sleep Mode Clock Gating Control
  [0] SYSCTL_DCGCQEI_D0 — [0:0] QEI Module 0 Deep-Sleep Mode Clock Gating Control
0x858 SYSCTL_DCGCEEPROM — EEPROM Deep-Sleep Mode Clock Gating Control
  [0] SYSCTL_DCGCEEPROM_D0 — [0:0] EEPROM Module Deep-Sleep Mode Clock Gating Control
0x874 SYSCTL_DCGCCCM — CRC and Cryptographic Modules Deep-Sleep Mode Clock Gating Control
  [0] SYSCTL_DCGCCCM_D0 — [0:0] CRC and Cryptographic Modules Deep-Sleep Mode Clock Gating Control
0x89C SYSCTL_DCGCEMAC — Ethernet MAC Deep-Sleep Mode Clock Gating Control
  [0] SYSCTL_DCGCEMAC_D0 — [0:0] Ethernet MAC Module 0 Deep-Sleep Mode Clock Gating Control
0x900 SYSCTL_PCWD — Watchdog Timer Power Control
  [1] SYSCTL_PCWD_P1 — [1:1] Watchdog Timer 1 Power Control
  [0] SYSCTL_PCWD_P0 — [0:0] Watchdog Timer 0 Power Control
0x904 SYSCTL_PCTIMER — 16/32-Bit General-Purpose Timer Power Control
  [n] SYSCTL_PCTIMER_P{n} (n=0..7) — [{n}:{n}] General-Purpose Timer {n} Power Control
0x908 SYSCTL_PCGPIO — General-Purpose Input/Output Power Control
  [14] SYSCTL_PCGPIO_P14 — [14:14] GPIO Port Q Power Control
  [13] SYSCTL_PCGPIO_P13 — [13:13] GPIO Port P Power Control
  [12] SYSCTL_PCGPIO_P12 — [12:12] GPIO Port N Power Control
  [11] SYSCTL_PCGPIO_P11 — [11:11] GPIO Port M Power Control
  [10] SYSCTL_PCGPIO_P10 — [10:10] GPIO Port L Power Control
  [9] SYSCTL_PCGPIO_P9 — [9:9] GPIO Port K Power Control
  [8] SYSCTL_PCGPIO_P8 — [8:8] GPIO Port J Power Control
  [7] SYSCTL_PCGPIO_P7 — [7:7] GPIO Port H Power Control
  [6] SYSCTL_PCGPIO_P6 — [6:6] GPIO Port G Power Control
  [5] SYSCTL_PCGPIO_P5 — [5:5] GPIO Port F Power Control
  [4] SYSCTL_PCGPIO_P4 — [4:4] GPIO Port E Power Control
  [3] SYSCTL_PCGPIO_P3 — [3:3] GPIO Port D Power Control
  [2] SYSCTL_PCGPIO_P2 — [2:2] GPIO Port C Power Control
  [1] SYSCTL_PCGPIO_P1 — [1:1] GPIO Port B Power Control
  [0] SYSCTL_PCGPIO_P0 — [0:0] GPIO Port A Power Control
0x90C SYSCTL_PCDMA — Micro Direct Memory Access Power Control
  [0] SYSCTL_PCDMA_P0 — [0:0] uDMA Module Power Control
0x910 SYSCTL_PCEPI — External Peripheral Interface Power Control
  [0] SYSCTL_PCEPI_P0 — [0:0] EPI Module Power Control
0x914 SYSCTL_PCHIB — Hibernation Power Control
  [0] SYSCTL_PCHIB_P0 — [0:0] Hibernation Module Power Control
0x918 SYSCTL_PCUART — Universal Asynchronous Receiver/Transmitter Power Control
  [n] SYSCTL_PCUART_P{n} (n=0..7) — [{n}:{n}] UART Module {n} Power Control
0x91C SYSCTL_PCSSI — Synchronous Serial Interface Power Control
  [n] SYSCTL_PCSSI_P{n} (n=0..3) — [{n}:{n}] SSI Module {n} Power Control
0x920 SYSCTL_PCI2C — Inter-Integrated Circuit Power Control
  [n] SYSCTL_PCI2C_P{n} (n=0..9) — [{n}:{n}] I2C Module {n} Power Control
0x928 SYSCTL_PCUSB — Universal Serial Bus Power Control
  [0] SYSCTL_PCUSB_P0 — [0:0] USB Module Power Control
0x930 SYSCTL_PCEPHY — Ethernet PHY Power Control
  [0] SYSCTL_PCEPHY_P0 — [0:0] Ethernet PHY Module Power Control
0x934 SYSCTL_PCCAN — Controller Area Network Power Control
  [1] SYSCTL_PCCAN_P1 — [1:1] CAN Module 1 Power Control
  [0] SYSCTL_PCCAN_P0 — [0:0] CAN Module 0 Power Control
0x938 SYSCTL_PCADC — Analog-to-Digital Converter Power Control
  [1] SYSCTL_PCADC_P1 — [1:1] ADC Module 1 Power Control
  [0] SYSCTL_PCADC_P0 — [0:0] ADC Module 0 Power Control
0x93C SYSCTL_PCACMP — Analog Comparator Power Control
  [0] SYSCTL_PCACMP_P0 — [0:0] Analog Comparator Module 0 Power Control
0x940 SYSCTL_PCPWM — Pulse Width Modulator Power Control
  [0] SYSCTL_PCPWM_P0 — [0:0] PWM Module 0 Power Control
0x944 SYSCTL_PCQEI — Quadrature Encoder Interface Power Control
  [0] SYSCTL_PCQEI_P0 — [0:0] QEI Module 0 Power Control
0x958 SYSCTL_PCEEPROM — EEPROM Power Control
  [0] SYSCTL_PCEEPROM_P0 — [0:0] EEPROM Module 0 Power Control
0x974 SYSCTL_PCCCM — CRC and Cryptographic Modules Power Control
  [0] SYSCTL_PCCCM_P0 — [0:0] CRC and Cryptographic Modules Power Control
0x99C SYSCTL_PCEMAC — Ethernet MAC Power Control
  [0] SYSCTL_PCEMAC_P0 — [0:0] Ethernet MAC Module 0 Power Control
0xA00 SYSCTL_PRWD — Watchdog Timer Peripheral Ready
  [1] SYSCTL_PRWD_R1 — [1:1] Watchdog Timer 1 Peripheral Ready
  [0] SYSCTL_PRWD_R0 — [0:0] Watchdog Timer 0 Peripheral Ready
0xA04 SYSCTL_PRTIMER — 16/32-Bit General-Purpose Timer Peripheral Ready
  [n] SYSCTL_PRTIMER_R{n} (n=0..7) — [{n}:{n}] 16/32-Bit General-Purpose Timer {n} Peripheral Ready
0xA08 SYSCTL_PRGPIO — General-Purpose Input/Output Peripheral Ready
  [14] SYSCTL_PRGPIO_R14 — [14:14] GPIO Port Q Peripheral Ready
  [13] SYSCTL_PRGPIO_R13 — [13:13] GPIO Port P Peripheral Ready
  [12] SYSCTL_PRGPIO_R12 — [12:12] GPIO Port N Peripheral Ready
  [11] SYSCTL_PRGPIO_R11 — [11:11] GPIO Port M Peripheral Ready
  [10] SYSCTL_PRGPIO_R10 — [10:10] GPIO Port L Peripheral Ready
  [9] SYSCTL_PRGPIO_R9 — [9:9] GPIO Port K Peripheral Ready
  [8] SYSCTL_PRGPIO_R8 — [8:8] GPIO Port J Peripheral Ready
  [7] SYSCTL_PRGPIO_R7 — [7:7] GPIO Port H Peripheral Ready
  [6] SYSCTL_PRGPIO_R6 — [6:6] GPIO Port G Peripheral Ready
  [5] SYSCTL_PRGPIO_R5 — [5:5] GPIO Port F Peripheral Ready
  [4] SYSCTL_PRGPIO_R4 — [4:4] GPIO Port E Peripheral Ready
  [3] SYSCTL_PRGPIO_R3 — [3:3] GPIO Port D Peripheral Ready
  [2] SYSCTL_PRGPIO_R2 — [2:2] GPIO Port C Peripheral Ready
  [1] SYSCTL_PRGPIO_R1 — [1:1] GPIO Port B Peripheral Ready
  [0] SYSCTL_PRGPIO_R0 — [0:0] GPIO Port A Peripheral Ready
0xA0C SYSCTL_PRDMA — Micro Direct Memory Access Peripheral Ready
  [0] SYSCTL_PRDMA_R0 — [0:0] uDMA Module Peripheral Ready
0xA10 SYSCTL_PREPI — EPI Peripheral Ready
  [0] SYSCTL_PREPI_R0 — [0:0] EPI Module Peripheral Ready
0xA14 SYSCTL_PRHIB — Hibernation Peripheral Ready
  [0] SYSCTL_PRHIB_R0 — [0:0] Hibernation Module Peripheral Ready
0xA18 SYSCTL_PRUART — Universal Asynchronous Receiver/Transmitter Peripheral Ready
  [n] SYSCTL_PRUART_R{n} (n=0..7) — [{n}:{n}] UART Module {n} Peripheral Ready
0xA1C SYSCTL_PRSSI — Synchronous Serial Interface Peripheral Ready
  [n] SYSCTL_PRSSI_R{n} (n=0..3) — [{n}:{n}] SSI Module {n} Peripheral Ready
0xA20 SYSCTL_PRI2C — Inter-Integrated Circuit Peripheral Ready
  [n] SYSCTL_PRI2C_R{n} (n=0..9) — [{n}:{n}] I2C Module {n} Peripheral Ready
0xA28 SYSCTL_PRUSB — Universal Serial Bus Peripheral Ready
  [0] SYSCTL_PRUSB_R0 — [0:0] USB Module Peripheral Ready
0xA30 SYSCTL_PREPHY — Ethernet PHY Peripheral Ready
  [0] SYSCTL_PREPHY_R0 — [0:0] Ethernet PHY Module Peripheral Ready
0xA34 SYSCTL_PRCAN — Controller Area Network Peripheral Ready
  [1] SYSCTL_PRCAN_R1 — [1:1] CAN Module 1 Peripheral Ready
  [0] SYSCTL_PRCAN_R0 — [0:0] CAN Module 0 Peripheral Ready
0xA38 SYSCTL_PRADC — Analog-to-Digital Converter Peripheral Ready
  [1] SYSCTL_PRADC_R1 — [1:1] ADC Module 1 Peripheral Ready
  [0] SYSCTL_PRADC_R0 — [0:0] ADC Module 0 Peripheral Ready
0xA3C SYSCTL_PRACMP — Analog Comparator Peripheral Ready
  [0] SYSCTL_PRACMP_R0 — [0:0] Analog Comparator Module 0 Peripheral Ready
0xA40 SYSCTL_PRPWM — Pulse Width Modulator Peripheral Ready
  [0] SYSCTL_PRPWM_R0 — [0:0] PWM Module 0 Peripheral Ready
0xA44 SYSCTL_PRQEI — Quadrature Encoder Interface Peripheral Ready
  [0] SYSCTL_PRQEI_R0 — [0:0] QEI Module 0 Peripheral Ready
0xA58 SYSCTL_PREEPROM — EEPROM Peripheral Ready
  [0] SYSCTL_PREEPROM_R0 — [0:0] EEPROM Module Peripheral Ready
0xA74 SYSCTL_PRCCM — CRC and Cryptographic Modules Peripheral Ready
  [0] SYSCTL_PRCCM_R0 — [0:0] CRC and Cryptographic Modules Peripheral Ready
0xA9C SYSCTL_PREMAC — Ethernet MAC Peripheral Ready
  [0] SYSCTL_PREMAC_R0 — [0:0] Ethernet MAC Module 0 Peripheral Ready
0x3F32204 SYSCTL_CCMCGREQ — Cryptographic Modules Clock Gating Request
  [2] SYSCTL_CCMCGREQ_DESCFG — [2:2] DES Clock Gating Request
  [1] SYSCTL_CCMCGREQ_AESCFG — [1:1] AES Clock Gating Request
  [0] SYSCTL_CCMCGREQ_SHACFG — [0:0] SHA/MD5 Clock Gating Request
